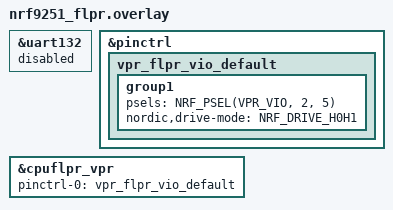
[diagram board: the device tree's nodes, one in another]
/*
 * Copyright (c) 2026 Nordic Semiconductor ASA
 *
 * SPDX-License-Identifier: LicenseRef-Nordic-5-Clause
 */

/*
 * Assign P2.05 (uart132 TX, wired to debugger UART1) to FLPR (VIO 8).
 *
 * GPIO -> VIO mapping:
 *     P5.1         -> 0
 *     P5.0         -> 1
 *     P5.2         -> 2
 *     P5.3         -> 3
 *     P5.4 / P2.0  -> 4
 *     P5.5 / P2.1  -> 5
 *     P2.2         -> 6
 *     P2.3         -> 7
 *     (P2.4 not connected)
 *     P2.5         -> 8
 *     P2.6         -> 9
 *     P2.7         -> 10
 *     P2.8         -> 11
 */
&uart132 {
	status = "disabled";
};

&pinctrl {
	vpr_flpr_vio_default: vpr_flpr_vio_default {
		group1 {
			psels = <NRF_PSEL(VPR_VIO, 2, 5)>;
			nordic,drive-mode = <NRF_DRIVE_H0H1>;
		};
	};
};

&cpuflpr_vpr {
	pinctrl-0 = <&vpr_flpr_vio_default>;
	pinctrl-names = "default";
};
